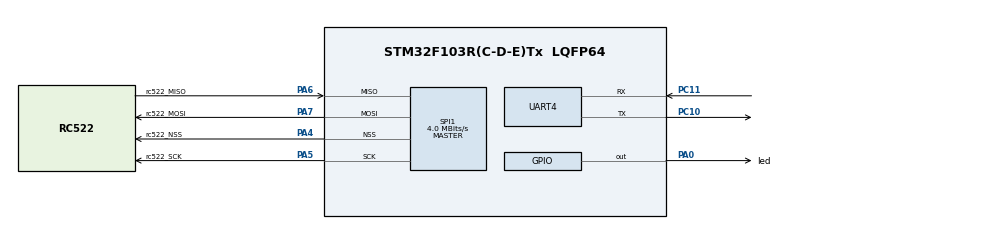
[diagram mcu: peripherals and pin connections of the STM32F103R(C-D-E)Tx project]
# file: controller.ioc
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Mcu.Family=STM32F1
Mcu.Name=STM32F103R(C-D-E)Tx
Mcu.Package=LQFP64
NVIC.PriorityGroup=NVIC_PRIORITYGROUP_4
PA0-WKUP.GPIO_Label=led
PA0-WKUP.PinState=GPIO_PIN_SET
PA0-WKUP.Signal=GPIO_Output
PA13.Mode=Serial_Wire
PA13.Signal=SYS_JTMS-SWDIO
PA14.Mode=Serial_Wire
PA14.Signal=SYS_JTCK-SWCLK
PA4.GPIO_Label=rc522_NSS
PA4.Mode=NSS_Signal_Hard_Output
PA4.Signal=SPI1_NSS
PA5.GPIO_Label=rc522_SCK
PA5.Mode=Full_Duplex_Master
PA5.Signal=SPI1_SCK
PA6.GPIO_Label=rc522_MISO
PA6.Mode=Full_Duplex_Master
PA6.Signal=SPI1_MISO
PA7.GPIO_Label=rc522_MOSI
PA7.Mode=Full_Duplex_Master
PA7.Signal=SPI1_MOSI
PC10.Mode=Asynchronous
PC10.Signal=UART4_TX
PC11.Mode=Asynchronous
PC11.Signal=UART4_RX
ProjectManager.HeapSize=0x200
ProjectManager.StackSize=0x400
ProjectManager.TargetToolchain=MDK-ARM V5.32
RCC.APB1Freq_Value=8000000
RCC.APB2Freq_Value=8000000
SPI1.CalculateBaudRate=4.0 MBits/s
SPI1.Direction=SPI_DIRECTION_2LINES
SPI1.Mode=SPI_MODE_MASTER
SPI1.VirtualNSS=VM_NSSHARD
SPI1.VirtualType=VM_MASTER
UART4.VirtualMode=Asynchronous
board=custom

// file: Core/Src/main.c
/* USER CODE BEGIN Header */
/**
  ******************************************************************************
  * @file           : main.c
  * @brief          : Main program body
  ******************************************************************************
  * @attention
  *
  * Copyright (c) 2024 STMicroelectronics.
  * All rights reserved.
  *
  * This software is licensed under terms that can be found in the LICENSE file
  * in the root directory of this software component.
  * If no LICENSE file comes with this software, it is provided AS-IS.
  *
  ******************************************************************************
  */
/* USER CODE END Header */
#include "../Inc/spi.h"
#include "../Inc/usart.h"
#include "../Inc/main.h"
#include "../Inc/gpio.h"
//#include "../../Drivers/MFRC522-1.4.11/src/MFRC522.h"
#include <stdbool.h>

void SystemClock_Config(void);

int main(void)
{

  /* USER CODE BEGIN 1 */
    bool isCardOnReader = false;
    uint8_t cardUID[7] = {};
    uint8_t cardKey[6] = {};
    uint8_t cardSectorData[16] = {};

  /* USER CODE END 1 */

  /* MCU Configuration--------------------------------------------------------*/

  /* Reset of all peripherals, Initializes the Flash interface and the Systick. */
  HAL_Init();

  /* Configure the system clock */
  SystemClock_Config();

  /* Initialize all configured peripherals */
  MX_GPIO_Init();
  MX_SPI1_Init();
  MX_UART4_Init();

  /* Infinite loop */
    while (1)
    {

    }
};

void SystemClock_Config(void)
{
  RCC_OscInitTypeDef RCC_OscInitStruct = {0};
  RCC_ClkInitTypeDef RCC_ClkInitStruct = {0};

  /** Initializes the RCC Oscillators according to the specified parameters
  * in the RCC_OscInitTypeDef structure.
  */
  RCC_OscInitStruct.OscillatorType = RCC_OSCILLATORTYPE_HSI;
  RCC_OscInitStruct.HSIState = RCC_HSI_ON;
  RCC_OscInitStruct.HSICalibrationValue = RCC_HSICALIBRATION_DEFAULT;
  RCC_OscInitStruct.PLL.PLLState = RCC_PLL_NONE;
  if (HAL_RCC_OscConfig(&RCC_OscInitStruct) != HAL_OK)
  {
    Error_Handler();
  }

  /** Initializes the CPU, AHB and APB buses clocks
  */
  RCC_ClkInitStruct.ClockType = RCC_CLOCKTYPE_HCLK|RCC_CLOCKTYPE_SYSCLK
                              |RCC_CLOCKTYPE_PCLK1|RCC_CLOCKTYPE_PCLK2;
  RCC_ClkInitStruct.SYSCLKSource = RCC_SYSCLKSOURCE_HSI;
  RCC_ClkInitStruct.AHBCLKDivider = RCC_SYSCLK_DIV1;
  RCC_ClkInitStruct.APB1CLKDivider = RCC_HCLK_DIV1;
  RCC_ClkInitStruct.APB2CLKDivider = RCC_HCLK_DIV1;

  if (HAL_RCC_ClockConfig(&RCC_ClkInitStruct, FLASH_LATENCY_0) != HAL_OK)
  {
    Error_Handler();
  }
}

void Error_Handler(void)
{
  __disable_irq();
  while (1)
  {
  }
}
